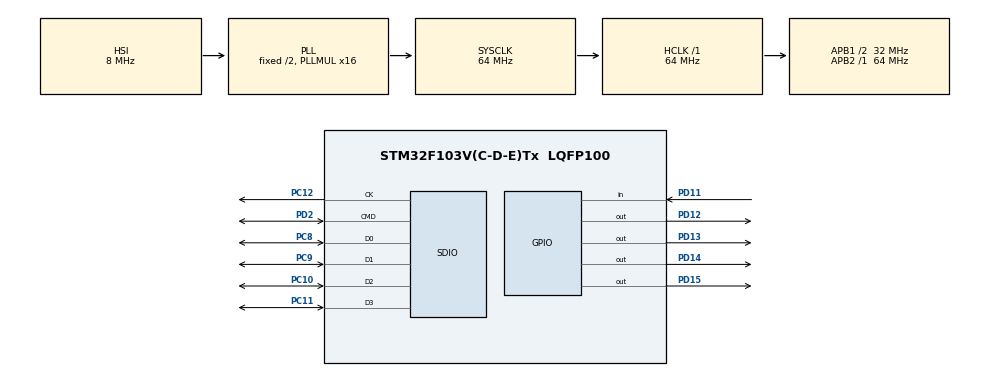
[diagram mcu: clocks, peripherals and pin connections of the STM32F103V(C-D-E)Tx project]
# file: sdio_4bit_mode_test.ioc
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Dma.Request0=SDIO
Dma.SDIO.0.Direction=DMA_PERIPH_TO_MEMORY
Dma.SDIO.0.Instance=DMA2_Channel4
Dma.SDIO.0.MemDataAlignment=DMA_MDATAALIGN_WORD
Dma.SDIO.0.MemInc=DMA_MINC_ENABLE
Dma.SDIO.0.Mode=DMA_NORMAL
Dma.SDIO.0.PeriphDataAlignment=DMA_PDATAALIGN_WORD
Dma.SDIO.0.PeriphInc=DMA_PINC_DISABLE
Dma.SDIO.0.Priority=DMA_PRIORITY_LOW
FATFS.BSP.number=1
FATFS._MAX_SS=4096
FATFS0.BSP.STBoard=false
FATFS0.BSP.api=Unknown
FATFS0.BSP.i2caddr=0
FATFS0.BSP.instance=PD11
FATFS0.BSP.ip=GPIO
FATFS0.BSP.mode=Input
FATFS0.BSP.name=Detect_SDIO
FATFS0.BSP.solution=PD11
Mcu.Family=STM32F1
Mcu.Name=STM32F103V(C-D-E)Tx
Mcu.Package=LQFP100
NVIC.DMA2_Channel4_5_IRQn=true\:0\:0\:false\:false\:true\:false\:true
NVIC.PriorityGroup=NVIC_PRIORITYGROUP_4
NVIC.SDIO_IRQn=true\:0\:0\:false\:false\:true\:true\:true
PC10.Mode=SD_4_bits_Wide_bus
PC10.Signal=SDIO_D2
PC11.Mode=SD_4_bits_Wide_bus
PC11.Signal=SDIO_D3
PC12.Mode=SD_4_bits_Wide_bus
PC12.Signal=SDIO_CK
PC8.Mode=SD_4_bits_Wide_bus
PC8.Signal=SDIO_D0
PC9.Mode=SD_4_bits_Wide_bus
PC9.Signal=SDIO_D1
PD11.Signal=GPIO_Input
PD12.Signal=GPIO_Output
PD13.Signal=GPIO_Output
PD14.Signal=GPIO_Output
PD15.Signal=GPIO_Output
PD2.Mode=SD_4_bits_Wide_bus
PD2.Signal=SDIO_CMD
ProjectManager.HeapSize=0x200
ProjectManager.StackSize=0x400
ProjectManager.TargetToolchain=MDK-ARM V5
RCC.AHBFreq_Value=64000000
RCC.APB1CLKDivider=RCC_HCLK_DIV2
RCC.APB1Freq_Value=32000000
RCC.APB1TimFreq_Value=64000000
RCC.APB2Freq_Value=64000000
RCC.APB2TimFreq_Value=64000000
RCC.HCLKFreq_Value=64000000
RCC.PLLMUL=RCC_PLL_MUL16
RCC.SYSCLKFreq_VALUE=64000000
RCC.SYSCLKSource=RCC_SYSCLKSOURCE_PLLCLK
RCC.USBFreq_Value=64000000
SDIO.ClockDiv=3
VP_FATFS_VS_SDIO.Mode=SDIO
VP_SYS_VS_ND.Mode=No_Debug
board=custom

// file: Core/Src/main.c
/* USER CODE BEGIN Header */
/**
  ******************************************************************************
  * @file           : main.c
  * @brief          : Main program body
  ******************************************************************************
  * @attention
  *
  * <h2><center>&copy; Copyright (c) 2021 STMicroelectronics.
  * All rights reserved.</center></h2>
  *
  * This software component is licensed by ST under Ultimate Liberty license
  * SLA0044, the "License"; You may not use this file except in compliance with
  * the License. You may obtain a copy of the License at:
  *                             www.st.com/SLA0044
  *
  ******************************************************************************
  */
/* USER CODE END Header */
#include "main.h"
#include "fatfs.h"

SD_HandleTypeDef hsd;
DMA_HandleTypeDef hdma_sdio;

void SystemClock_Config(void);
static void MX_GPIO_Init(void);
static void MX_SDIO_SD_Init(void);
static void MX_DMA_Init(void);

/* USER CODE BEGIN 0 */
FATFS myFatFS;
FIL myFile;
UINT myBytes;
/* USER CODE END 0 */

int main(void)
{

  /* MCU Configuration--------------------------------------------------------*/

  /* Reset of all peripherals, Initializes the Flash interface and the Systick. */
  HAL_Init();

  /* Configure the system clock */
  SystemClock_Config();

  /* Initialize all configured peripherals */
  MX_GPIO_Init();
  MX_SDIO_SD_Init();
  MX_DMA_Init();
  MX_FATFS_Init();
  /* USER CODE BEGIN 2 */
if(f_mount(&myFatFS, SDPath, 1) == FR_OK){
	HAL_GPIO_WritePin(GPIOD, GPIO_PIN_12, GPIO_PIN_SET);

	char myFileName[] = "TEST1.txt";
	if(f_open(&myFile, myFileName, FA_WRITE | FA_CREATE_ALWAYS) == FR_OK){
		HAL_GPIO_WritePin(GPIOD, GPIO_PIN_13, GPIO_PIN_SET);
		char myData[] = "Hello from STM32F1, SDIO in 4 bits mode";
		if(f_write(&myFile, myData, sizeof(myData), &myBytes) == FR_OK){
			HAL_GPIO_WritePin(GPIOD, GPIO_PIN_15, GPIO_PIN_SET);
		}
		f_close(&myFile);
	}
}
else{
	HAL_GPIO_WritePin(GPIOD, GPIO_PIN_14, GPIO_PIN_SET);
}

  /* USER CODE END 2 */

  /* Infinite loop */
  while (1)
  {

  }
}

void SystemClock_Config(void)
{
  RCC_OscInitTypeDef RCC_OscInitStruct = {0};
  RCC_ClkInitTypeDef RCC_ClkInitStruct = {0};

  /** Initializes the RCC Oscillators according to the specified parameters
  * in the RCC_OscInitTypeDef structure.
  */
  RCC_OscInitStruct.OscillatorType = RCC_OSCILLATORTYPE_HSI;
  RCC_OscInitStruct.HSIState = RCC_HSI_ON;
  RCC_OscInitStruct.HSICalibrationValue = RCC_HSICALIBRATION_DEFAULT;
  RCC_OscInitStruct.PLL.PLLState = RCC_PLL_ON;
  RCC_OscInitStruct.PLL.PLLSource = RCC_PLLSOURCE_HSI_DIV2;
  RCC_OscInitStruct.PLL.PLLMUL = RCC_PLL_MUL16;
  if (HAL_RCC_OscConfig(&RCC_OscInitStruct) != HAL_OK)
  {
    Error_Handler();
  }
  /** Initializes the CPU, AHB and APB buses clocks
  */
  RCC_ClkInitStruct.ClockType = RCC_CLOCKTYPE_HCLK|RCC_CLOCKTYPE_SYSCLK
                              |RCC_CLOCKTYPE_PCLK1|RCC_CLOCKTYPE_PCLK2;
  RCC_ClkInitStruct.SYSCLKSource = RCC_SYSCLKSOURCE_PLLCLK;
  RCC_ClkInitStruct.AHBCLKDivider = RCC_SYSCLK_DIV1;
  RCC_ClkInitStruct.APB1CLKDivider = RCC_HCLK_DIV2;
  RCC_ClkInitStruct.APB2CLKDivider = RCC_HCLK_DIV1;

  if (HAL_RCC_ClockConfig(&RCC_ClkInitStruct, FLASH_LATENCY_2) != HAL_OK)
  {
    Error_Handler();
  }
}

static void MX_SDIO_SD_Init(void)
{

  hsd.Instance = SDIO;
  hsd.Init.ClockEdge = SDIO_CLOCK_EDGE_RISING;
  hsd.Init.ClockBypass = SDIO_CLOCK_BYPASS_DISABLE;
  hsd.Init.ClockPowerSave = SDIO_CLOCK_POWER_SAVE_DISABLE;
  hsd.Init.BusWide = SDIO_BUS_WIDE_1B;
  hsd.Init.HardwareFlowControl = SDIO_HARDWARE_FLOW_CONTROL_DISABLE;
  hsd.Init.ClockDiv = 3;

}

static void MX_DMA_Init(void)
{

  /* DMA controller clock enable */
  __HAL_RCC_DMA2_CLK_ENABLE();

  /* DMA interrupt init */
  /* DMA2_Channel4_5_IRQn interrupt configuration */
  HAL_NVIC_SetPriority(DMA2_Channel4_5_IRQn, 0, 0);
  HAL_NVIC_EnableIRQ(DMA2_Channel4_5_IRQn);

}

static void MX_GPIO_Init(void)
{
  GPIO_InitTypeDef GPIO_InitStruct = {0};

  /* GPIO Ports Clock Enable */
  __HAL_RCC_GPIOD_CLK_ENABLE();
  __HAL_RCC_GPIOC_CLK_ENABLE();

  /*Configure GPIO pin Output Level */
  HAL_GPIO_WritePin(GPIOD, GPIO_PIN_12|GPIO_PIN_13|GPIO_PIN_14|GPIO_PIN_15, GPIO_PIN_RESET);

  /*Configure GPIO pin : PD11 */
  GPIO_InitStruct.Pin = GPIO_PIN_11;
  GPIO_InitStruct.Mode = GPIO_MODE_INPUT;
  GPIO_InitStruct.Pull = GPIO_NOPULL;
  HAL_GPIO_Init(GPIOD, &GPIO_InitStruct);

  /*Configure GPIO pins : PD12 PD13 PD14 PD15 */
  GPIO_InitStruct.Pin = GPIO_PIN_12|GPIO_PIN_13|GPIO_PIN_14|GPIO_PIN_15;
  GPIO_InitStruct.Mode = GPIO_MODE_OUTPUT_PP;
  GPIO_InitStruct.Pull = GPIO_NOPULL;
  GPIO_InitStruct.Speed = GPIO_SPEED_FREQ_LOW;
  HAL_GPIO_Init(GPIOD, &GPIO_InitStruct);

}

void Error_Handler(void)
{
  __disable_irq();
  while (1)
  {
  }
}

/************************ (C) COPYRIGHT STMicroelectronics *****END OF FILE****/
